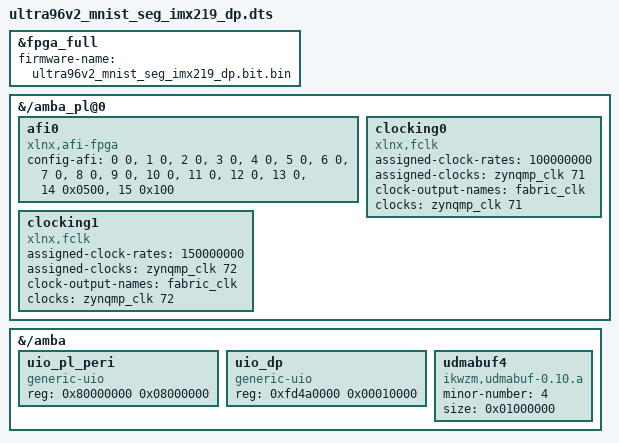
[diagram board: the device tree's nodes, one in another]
/dts-v1/; /plugin/;

/ {
    fragment@0 {
        target = <&fpga_full>;
        __overlay__ {
            #address-cells = <2>;
            #size-cells = <2>;
            firmware-name = "ultra96v2_mnist_seg_imx219_dp.bit.bin";
        };
    };
    
    fragment@1 {
        target-path = "/amba_pl@0";
        
        #address-cells = <2>;
        #size-cells = <2>;
        __overlay__ {
            #address-cells = <2>;
            #size-cells = <2>;
            afi0 {
                compatible    = "xlnx,afi-fpga";
                config-afi    = <0  0>,     /* S_AXI_HPC0_FPD(read)  : 0:128bit, 1:64bit, 2:32bit */
                                <1  0>,     /* S_AXI_HPC0_FPD(write) : 0:128bit, 1:64bit, 2:32bit */
                                <2  0>,     /* S_AXI_HPC1_FPD(read)  : 0:128bit, 1:64bit, 2:32bit */
                                <3  0>,     /* S_AXI_HPC1_FPD(write) : 0:128bit, 1:64bit, 2:32bit */
                                <4  0>,     /* S_AXI_HP0_FPD(read)   : 0:128bit, 1:64bit, 2:32bit */
                                <5  0>,     /* S_AXI_HP0_FPD(write)  : 0:128bit, 1:64bit, 2:32bit */
                                <6  0>,     /* S_AXI_HP1_FPD(read)   : 0:128bit, 1:64bit, 2:32bit */
                                <7  0>,     /* S_AXI_HP1_FPD(write)  : 0:128bit, 1:64bit, 2:32bit */
                                <8  0>,     /* S_AXI_HP2_FPD(read)   : 0:128bit, 1:64bit, 2:32bit */
                                <9  0>,     /* S_AXI_HP2_FPD(write)  : 0:128bit, 1:64bit, 2:32bit */
                                <10 0>,     /* S_AXI_HP3_FPD(read)   : 0:128bit, 1:64bit, 2:32bit */
                                <11 0>,     /* S_AXI_HP3_FPD(write)  : 0:128bit, 1:64bit, 2:32bit */
                                <12 0>,     /* S_AXI_LPD(read)       : 0:128bit, 1:64bit, 2:32bit */
                                <13 0>,     /* S_AXI_LPD(write)      : 0:128bit, 1:64bit, 2:32bit */
                                <14 0x0500>,/* M_AXI_HPM0_FPD[9:8], M_AXI_HPM0_FPD[11:10] : 0:32bit, 1:64bit, 2:128bit */
                                <15 0x100>; /* M_AXI_HPM0_LPD        : 0x000:32bit, 0x100:64bit, 0x200:128bit */
            };
            clocking0: clocking0 {
                #clock-cells = <0>;
                assigned-clock-rates = <100000000>;
                assigned-clocks = <&zynqmp_clk 71>;
                clock-output-names = "fabric_clk";
                clocks = <&zynqmp_clk 71>;
                compatible = "xlnx,fclk";
            };
            clocking1: clocking1 {
                #clock-cells = <0>;
                assigned-clock-rates = <150000000>;
                assigned-clocks = <&zynqmp_clk 72>;
                clock-output-names = "fabric_clk";
                clocks = <&zynqmp_clk 72>;
                compatible = "xlnx,fclk";
            };
        };
    } ;
    
    fragment@2 {
        target-path = "/amba";
        __overlay__ {
            #address-cells = <0x1>;
            #size-cells = <0x1>;
            
            uio_pl_peri {
                compatible = "generic-uio";
                reg = <0x80000000 0x08000000>;
            };

            uio_dp {
                compatible = "generic-uio";
                reg = <0xfd4a0000 0x00010000>;
            };
            
            udmabuf4 {
                compatible = "ikwzm,udmabuf-0.10.a";
                minor-number = <4>;
                size = <0x01000000>;
            };
        };
    };
};

